# ExynosT100 register map
Vendor: SAMSUNG System LSI; Series: ARMCM4F; File version: 0.1
CPU: CM4 r1p0, little endian, MPU, FPU, 3 interrupt priority bits
Registers are 32-bit, read-write, reset 0x0 unless marked. A register's access mark holds for its fields unless they carry their own. Offsets are from the block's base; [hi:lo] are bit positions; {n}, {i} and the like mark numbered series.

## TMR0 — 16-bit simple timer
Base 0x400A0000
Same registers: TMR1 0x400A0010, TMR2 0x400A0020, TMR3 0x400A0030, TMR4 0x400A0040
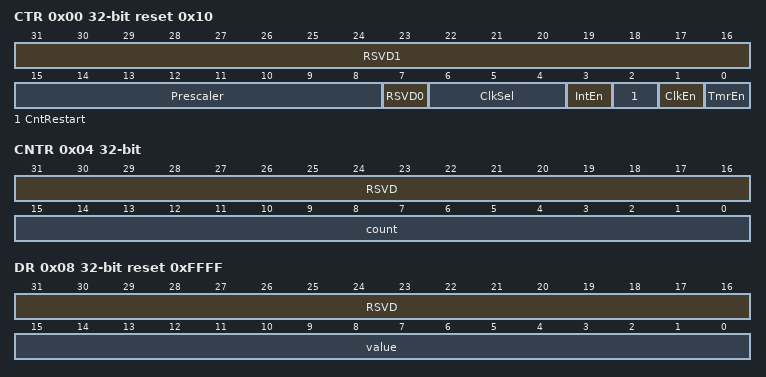
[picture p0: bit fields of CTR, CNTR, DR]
0x00 CTR reset 0x10 — 16-Bit Timer Control Register
  [31:16] RSVD1 ro
  [15:8] Prescaler — Prescaler bit bits contain 8 bits prescaler value bits 0x00 = Timer clock is divided by 1 0xFF = Timer clock is divided by 256
  [7] RSVD0 ro
  [6:4] ClkSel — Timer input clock selection bit 000 = DS_DCXO 32 MHz 001 = System clock (HCLKperi)(default) 011 = Crystal Oscillator (32.768 kHz, XTAL) 101 = Low frequency (30 kHz) DS RCO 111 = Low frequency (10 kHz) UDS RCO
  [3] IntEn — Timer interrupt control bit This bit enables or disables timer interrupt function. 0 = Disable 1 = Enable
  [2] CntRestart — Counter restart control bit This bit determines a counting method. 0 = Free run (Counter register value increments after matching with the data value, CNTR[15:0]) 1 = Restart (Counter register value is cleared and counting is resumed from 0x0000 after matching with the data value)
  [1] ClkEn — Timer clock control bit This bit enables or disables the clock source for the timers 0 = Disable (Counter is stopped) 1 = Enable (Counter is started again)
  [0] TmrEn — Timer operation control bit This bit controls the timer operation. 0 = Reset timer in CNTR and disables counter operation 1 = Enables counter operation. The counter value is increased by 1 on accepting every clock.
0x04 CNTR — 16-Bit Timer Counter Register
  [31:16] RSVD ro
  [15:0] count ro — 16 bits counter value bits For more information on timer counter value, refer to CTR[2].
0x08 DR reset 0xFFFF — 16-Bit Timer Data Register
  [31:16] RSVD ro, [15:0] value

## WDT — 20-bit WatchdogTimer
Base 0x400A0080
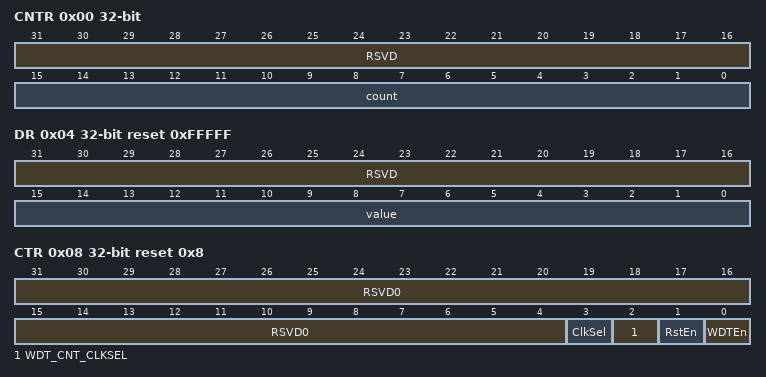
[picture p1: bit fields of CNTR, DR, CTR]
0x00 CNTR — 20 Bits Watchdog Timer Counter Register
  [31:16] RSVD ro
  [15:0] count ro — 16 bits counter value bits For more information on timer counter value, refer to CTR[2].
0x04 DR reset 0xFFFFF — 20-Bit Watchdog Timer Data Register
  [31:16] RSVD ro, [15:0] value
0x08 CTR reset 0x8 — 20-Bit Watchdog Timer Control Register
  [31:4] RSVD0 ro
  [3] ClkSel — Watchdog clock source selection bit 0 = DCXO 32 MHz 1 = System clock (HCLKperi)
  [2] WDT_CNT_CLKSEL — Counter clock selection bit (pre-scalar) 0 = Clock is divided by 256 (precount: 0x100) 1 = Clock bypass (precount: 0x1)
  [1] RstEn — Chip reset control bit 0 = Chip does not enter RESET state when the watchdog timer interrupt is occurred. 1 = Chip enters RESET state when the watchdog timer interrupt is occurred.
  [0] WDTEn — Watchdog timer operation control bit 0 = Reset watchdog timer and disable counter operation 1 = Enable counter operation

## PWM0 — PWM
Base 0x400A0400
Same registers: PWM1 0x400A0500
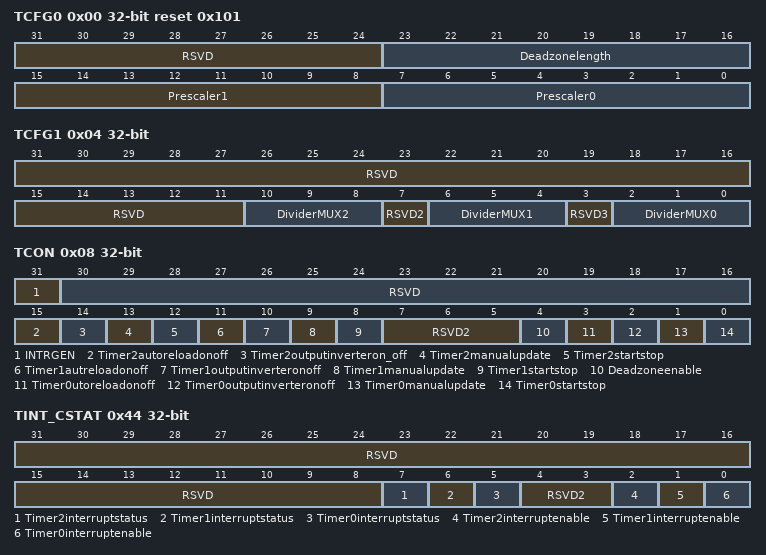
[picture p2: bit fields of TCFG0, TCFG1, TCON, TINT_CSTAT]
0x00 TCFG0 reset 0x101 — Timer Configuration Register 0 that configures the two 8-bit prescaler and dead zone length
  [31:24] RSVD ro
  [23:16] Deadzonelength
  [15:8] Prescaler1 — Prescaler 1 value for timer 2
  [7:0] Prescaler0 — Prescaler 1 value for timer 0 and 1
0x04 TCFG1 — Timer Configuration Register 1 that controls 3 mux select bit
  [31:11] RSVD ro
  [10:8] DividerMUX2 — Selects mux input for PWM timer2 000 = 1/1 001 = 1/2 010 = 1/4 011 = 1/8 100 = 1/16
  [7] RSVD2 ro
  [6:4] DividerMUX1 — Selects mux input for PWM timer 1 000 = 1/1 001 = 1/2 010 = 1/4 011 = 1/8 100 = 1/16
  [3] RSVD3 ro
  [2:0] DividerMUX0 — Selects mux input for PWM timer0 000 = 1/1 001 = 1/2 010 = 1/4 011 = 1/8 100 = 1/16
0x08 TCON — Timer Control Register
  [31] INTRGEN — PWM interrupt selection 0 = Edge trigger 1 = Level trigger
  [30:16] RSVD ro
  [15] Timer2autoreloadonoff — Enables the auto reload of timer 2 0 = One-shot 1 = Interval mode (Auto-reload)
  [14] Timer2outputinverteron_off — Enables the output inverter of timer 2 0 = Inverter off 1 = TOUT_2 inverter-on
  [13] Timer2manualupdate — Manual update of timer 2 0 = No operation 1 = Updates TCNTB2 and TCMPB2
  [12] Timer2startstop — Start of timer 2 0 = Stops the timer 2 1 = Starts the timer 2
  [11] Timer1autreloadonoff — Enables the auto reload of timer 1 0 = One-shot 1 = Interval mode (Auto-reload)
  [10] Timer1outputinverteronoff — Enables the output inverter of timer 1 0 = Inverter off 1 = TOUT_1 inverter-on
  [9] Timer1manualupdate — Manual update of timer 1 0 = No operation 1 = Updates TCNTB1 and TCMPB1
  [8] Timer1startstop — Start of timer 1 0 = Stops the timer 1 1 = Starts the timer 1
  [7:5] RSVD2
  [4] Deadzoneenable — Dead zone generator enable/disable 0 = Disable 1 = Enable
  [3] Timer0utoreloadonoff — Enables the auto reload of timer 0 0 = One-shot 1 = Interval mode (Auto-reload)
  [2] Timer0outputinverteronoff — Enables the output inverter of timer 0 0 = Inverter off 1 = TOUT_0 inverter-on
  [1] Timer0manualupdate — Manual update of timer 0 0 = No operation 1 = Updates TCNTB0 and TCMPB0
  [0] Timer0startstop — Start of timer 0 0 = Stops the timer 0 1 = Starts the timer 0
0x0C TCNTB0 — Timer 0 Count Buffer Register
  [31:0] Timer0countbuffer
0x10 TCMPB0 — Timer 0 Compare Buffer Register
  [31:0] Timer0comparebuffer
0x14 TCNTO0 — Timer 0 Count Observation Register
  [31:0] Timer0countobservation
0x18 TCNTB1 — Timer 1 Count Buffer Register
  [31:0] Timer1countbuffer — Timer 0 compare buffer register
0x1C TCMPB1 — Timer 1 Compare Buffer Register
  [31:0] Timer1comparebuffer — Timer 0 compare buffer register
0x20 TCNTO1 ro — Timer 1 Count Observation Register
  [31:0] Timer1countobservation
0x24 TCNTB2 — Timer 2 Count Buffer Register
  [31:0] Timer2countbuffer
0x28 TCMPB2 — Timer 2 Compare Buffer Register
  [31:0] Timer2comparebuffer
0x2C TCNTO2 ro — Timer 2 Count Observation Register
  [31:0] Timer2countobservation
0x44 TINT_CSTAT — Timer Interrupt Control and Status Register
  [31:8] RSVD ro
  [7] Timer2interruptstatus rw-once — Timer 2 interrupt status bit Write 1 to clear this bit.
  [6] Timer1interruptstatus rw-once — Timer 1 interrupt status bit Write 1 to clear this bit.
  [5] Timer0interruptstatus rw-once — Timer 0 interrupt status bit Write 1 to clear this bit.
  [4:3] RSVD2 ro
  [2] Timer2interruptenable — Enables timer 2 Interrupt 0 = Disable 1 = Enable
  [1] Timer1interruptenable — Enables timer 1 Interrupt 0 = Disable 1 = Enable
  [0] Timer0interruptenable — Enables timer 0 Interrupt 0 = Disable 1 = Enable

## RESET — Reset Control
Base 0x40080C00
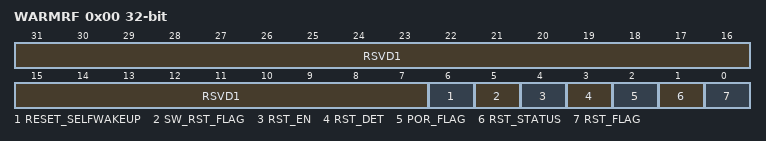
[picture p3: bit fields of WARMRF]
0x00 WARMRF — It's Register
  [31:7] RSVD1 ro
  [6] RESET_SELFWAKEUP — Resets self wake-up when WDT(watch dog timer) reset asserts 0 = Hold reset until next POR 1 = Self wake-up from WDT reset Caution: In order to system reset by Watch Dog Timer, must set this bit
  [5] SW_RST_FLAG rw-once — S/W reset flag bit (Read) raised by SYSRESETREQ 0 = S/W reset is not detected 1 = S/W reset is detected If we write 1 to this bit, this bit goes to 0 (write 1 clear).
  [4] RST_EN — 0 = NRESET is treated as an interrupt (default) 1 = NRESET is treated as system reset signal
  [3] RST_DET rw-once — 0 : not detected 1 : wdt reset detected If write 1 to this bit, this bit will be go to 0.(write 1 clear)
  [2] POR_FLAG ro — S/W reset flag bit (read only) 0 = Internal POR level is low 1 = Internal POR level is high
  [1] RST_STATUS ro — Reset status (from pad NRESET) bit (read only) 0 = Status of pad NRESET signal is logic-low (Reset state) 1 = Status of pad NRESET signal is logic-high (Reset released state)
  [0] RST_FLAG ro — Warm reset flag bit (read only) NRESET falling is detected 0 = NRESET falling is not detected 1 = NRESET falling is detected

## AES
Base 0x40100000
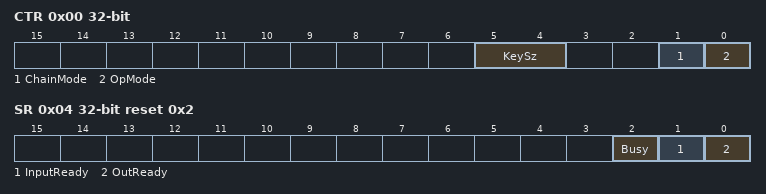
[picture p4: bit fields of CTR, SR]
0x00 CTR — Offset: 0x0000 AES Control Register
  [5:4] KeySz — AES key size selection signal
  [1] ChainMode — AES chain mode selection signal
  [0] OpMode — Encryption/decryption mode selection signal
0x04 SR reset 0x2 — Offset: 0x0004 AES Status Register
  [2] Busy ro — AES busy signal
  [1] InputReady ro — AES input ready signal
  [0] OutReady — AES output ready signal
{0xC+4i} IDR[{i}] (i=1..4) — Offset: 0x0010 AES Input Data Register
  [31:0] Value — AES input data
{0x1C+4i} ODR[{i}] (i=1..4) — Offset: 0x0020 AES Output Data Register
  [31:0] Value — AES output data
{0x4C+4i} IVR[{i}] (i=1..4) — Offset: 0x0050 AES initial vector register
  [31:0] Value — AES initial vector
{0x7C+4i} KDR[{i}] (i=1..8) — Offset: 0x0080 AES Key Register
  [31:0] Value — AES Key
